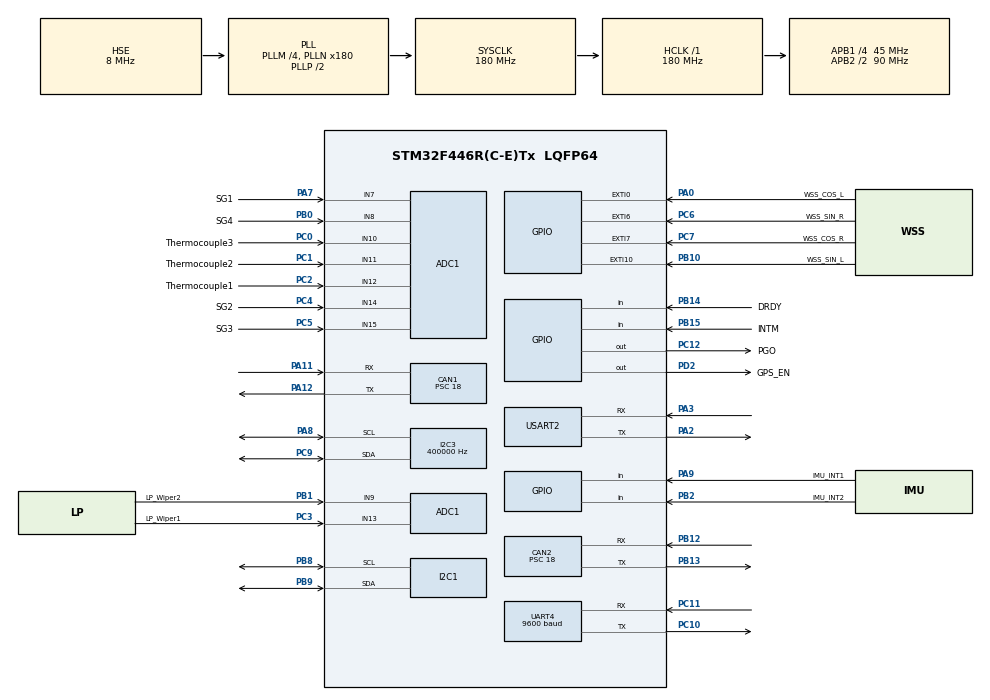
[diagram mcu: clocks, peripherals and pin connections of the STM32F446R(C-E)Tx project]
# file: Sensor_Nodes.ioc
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ADC1.Channel-0\#ChannelRegularConversion=ADC_CHANNEL_13
ADC1.NbrOfConversionFlag=1
ADC1.Rank-0\#ChannelRegularConversion=1
ADC1.SamplingTime-0\#ChannelRegularConversion=ADC_SAMPLETIME_3CYCLES
ADC1.master=1
CAN1.BS1=CAN_BS1_3TQ
CAN1.CalculateBaudRate=500000
CAN1.CalculateTimeBit=2000
CAN1.CalculateTimeQuantum=400.0
CAN1.Prescaler=18
CAN2.BS1=CAN_BS1_3TQ
CAN2.CalculateBaudRate=500000
CAN2.CalculateTimeBit=2000
CAN2.CalculateTimeQuantum=400.0
CAN2.Prescaler=18
Dma.Request0=USART2_RX
Dma.Request1=USART2_TX
Dma.Request2=UART4_RX
Dma.Request3=UART4_TX
Dma.UART4_RX.2.Direction=DMA_PERIPH_TO_MEMORY
Dma.UART4_RX.2.FIFOMode=DMA_FIFOMODE_DISABLE
Dma.UART4_RX.2.Instance=DMA1_Stream2
Dma.UART4_RX.2.MemDataAlignment=DMA_MDATAALIGN_BYTE
Dma.UART4_RX.2.MemInc=DMA_MINC_ENABLE
Dma.UART4_RX.2.Mode=DMA_CIRCULAR
Dma.UART4_RX.2.PeriphDataAlignment=DMA_PDATAALIGN_BYTE
Dma.UART4_RX.2.PeriphInc=DMA_PINC_DISABLE
Dma.UART4_RX.2.Priority=DMA_PRIORITY_LOW
Dma.UART4_TX.3.Direction=DMA_MEMORY_TO_PERIPH
Dma.UART4_TX.3.FIFOMode=DMA_FIFOMODE_DISABLE
Dma.UART4_TX.3.Instance=DMA1_Stream4
Dma.UART4_TX.3.MemDataAlignment=DMA_MDATAALIGN_BYTE
Dma.UART4_TX.3.MemInc=DMA_MINC_ENABLE
Dma.UART4_TX.3.Mode=DMA_NORMAL
Dma.UART4_TX.3.PeriphDataAlignment=DMA_PDATAALIGN_BYTE
Dma.UART4_TX.3.PeriphInc=DMA_PINC_DISABLE
Dma.UART4_TX.3.Priority=DMA_PRIORITY_LOW
Dma.USART2_RX.0.Direction=DMA_PERIPH_TO_MEMORY
Dma.USART2_RX.0.FIFOMode=DMA_FIFOMODE_DISABLE
Dma.USART2_RX.0.Instance=DMA1_Stream5
Dma.USART2_RX.0.MemDataAlignment=DMA_MDATAALIGN_BYTE
Dma.USART2_RX.0.MemInc=DMA_MINC_ENABLE
Dma.USART2_RX.0.Mode=DMA_CIRCULAR
Dma.USART2_RX.0.PeriphDataAlignment=DMA_PDATAALIGN_BYTE
Dma.USART2_RX.0.PeriphInc=DMA_PINC_DISABLE
Dma.USART2_RX.0.Priority=DMA_PRIORITY_LOW
Dma.USART2_TX.1.Direction=DMA_MEMORY_TO_PERIPH
Dma.USART2_TX.1.FIFOMode=DMA_FIFOMODE_DISABLE
Dma.USART2_TX.1.Instance=DMA1_Stream6
Dma.USART2_TX.1.MemDataAlignment=DMA_MDATAALIGN_BYTE
Dma.USART2_TX.1.MemInc=DMA_MINC_ENABLE
Dma.USART2_TX.1.Mode=DMA_NORMAL
Dma.USART2_TX.1.PeriphDataAlignment=DMA_PDATAALIGN_BYTE
Dma.USART2_TX.1.PeriphInc=DMA_PINC_DISABLE
Dma.USART2_TX.1.Priority=DMA_PRIORITY_LOW
FREERTOS.CountingSemaphores01=canTxMailboxSem,3,Dynamic,NULL,3
FREERTOS.Mutexes01=canTxMutex,Dynamic,NULL,Available;canRxMutex,Dynamic,NULL,Available;logMutex,Dynamic,NULL,Available;uartTxMutex,Dynamic,NULL,Available
FREERTOS.Queues01=canTxQueue,16,FEB_CAN_Message_t,0,Dynamic,NULL,NULL;canRxQueue,32,FEB_CAN_Message_t,0,Dynamic,NULL,NULL;uartRxQueue,8,FEB_UART_RxQueueMsg_t,0,Dynamic,NULL,NULL
FREERTOS.Tasks01=defaultTask,24,128,StartDefaultTask,Default,NULL,Dynamic,NULL,NULL;uartRxTask,24,1024,StartUartRxTask,As weak,NULL,Dynamic,NULL,NULL;canRxTask,40,1024,StartCanRxTask,As weak,NULL,Dynamic,NULL,NULL;canTxTask,40,1024,StartCanTxTask,As weak,NULL,Dynamic,NULL,NULL;canPubTask,40,512,StartCanPubTask,As weak,NULL,Dynamic,NULL,NULL;sensorTask,32,1024,StartSensorTask,As weak,NULL,Dynamic,NULL,NULL
FREERTOS.configTOTAL_HEAP_SIZE=32768
FREERTOS.configUSE_COUNTING_SEMAPHORES=1
FREERTOS.configUSE_TIMERS=0
I2C3.ClockSpeed=400000
I2C3.I2C_Mode=I2C_Fast
Mcu.Family=STM32F4
Mcu.Name=STM32F446R(C-E)Tx
Mcu.Package=LQFP64
NVIC.CAN1_RX0_IRQn=true\:5\:0\:false\:false\:true\:true\:true\:true\:true
NVIC.CAN1_RX1_IRQn=true\:5\:0\:false\:false\:true\:true\:true\:true\:true
NVIC.CAN1_SCE_IRQn=true\:5\:0\:false\:false\:true\:true\:true\:true\:true
NVIC.CAN1_TX_IRQn=true\:5\:0\:false\:false\:true\:true\:true\:true\:true
NVIC.CAN2_RX0_IRQn=true\:5\:0\:false\:false\:true\:true\:true\:true\:true
NVIC.CAN2_RX1_IRQn=true\:5\:0\:false\:false\:true\:true\:true\:true\:true
NVIC.CAN2_SCE_IRQn=true\:5\:0\:false\:false\:true\:true\:true\:true\:true
NVIC.CAN2_TX_IRQn=true\:5\:0\:false\:false\:true\:true\:true\:true\:true
NVIC.DMA1_Stream2_IRQn=true\:5\:0\:false\:false\:true\:true\:false\:true\:true
NVIC.DMA1_Stream4_IRQn=true\:5\:0\:false\:false\:true\:true\:false\:true\:true
NVIC.DMA1_Stream5_IRQn=true\:5\:0\:false\:false\:true\:true\:false\:true\:true
NVIC.DMA1_Stream6_IRQn=true\:5\:0\:false\:false\:true\:true\:false\:true\:true
NVIC.EXTI0_IRQn=true\:5\:0\:false\:false\:true\:true\:true\:true\:true
NVIC.EXTI15_10_IRQn=true\:5\:0\:false\:false\:true\:true\:true\:true\:true
NVIC.EXTI9_5_IRQn=true\:5\:0\:false\:false\:true\:true\:true\:true\:true
NVIC.PriorityGroup=NVIC_PRIORITYGROUP_4
NVIC.UART4_IRQn=true\:5\:0\:false\:false\:true\:true\:true\:true\:true
NVIC.USART2_IRQn=true\:5\:0\:false\:false\:true\:true\:true\:true\:true
PA0-WKUP.GPIO_Label=WSS_COS_L
PA0-WKUP.GPIO_ModeDefaultEXTI=GPIO_MODE_IT_RISING_FALLING
PA0-WKUP.Signal=GPXTI0
PA11.Mode=CAN_Activate
PA11.Signal=CAN1_RX
PA12.Mode=CAN_Activate
PA12.Signal=CAN1_TX
PA13.Mode=JTAG_5_pins
PA13.Signal=SYS_JTMS-SWDIO
PA14.Mode=JTAG_5_pins
PA14.Signal=SYS_JTCK-SWCLK
PA15.Mode=JTAG_5_pins
PA15.Signal=SYS_JTDI
PA2.Mode=Asynchronous
PA2.Signal=USART2_TX
PA3.Mode=Asynchronous
PA3.Signal=USART2_RX
PA7.GPIO_Label=SG1
PA7.Signal=ADCx_IN7
PA8.Mode=I2C
PA8.Signal=I2C3_SCL
PA9.GPIO_Label=IMU_INT1
PA9.Signal=GPIO_Input
PB0.GPIO_Label=SG4
PB0.Signal=ADCx_IN8
PB1.GPIO_Label=LP_Wiper2
PB1.Signal=ADCx_IN9
PB10.GPIO_Label=WSS_SIN_L
PB10.GPIO_ModeDefaultEXTI=GPIO_MODE_IT_RISING_FALLING
PB10.Signal=GPXTI10
PB12.Mode=CAN_Activate
PB12.Signal=CAN2_RX
PB13.Mode=CAN_Activate
PB13.Signal=CAN2_TX
PB14.GPIO_Label=DRDY
PB14.Signal=GPIO_Input
PB15.GPIO_Label=INTM
PB15.Signal=GPIO_Input
PB2.GPIO_Label=IMU_INT2
PB2.Signal=GPIO_Input
PB3.Mode=JTAG_5_pins
PB3.Signal=SYS_JTDO-SWO
PB4.Mode=JTAG_5_pins
PB4.Signal=SYS_JTRST
PB8.Mode=I2C
PB8.Signal=I2C1_SCL
PB9.Mode=I2C
PB9.Signal=I2C1_SDA
PC0.GPIO_Label=Thermocouple3
PC0.Signal=ADCx_IN10
PC1.GPIO_Label=Thermocouple2
PC1.Signal=ADCx_IN11
PC10.Mode=Asynchronous
PC10.Signal=UART4_TX
PC11.Mode=Asynchronous
PC11.Signal=UART4_RX
PC12.GPIO_Label=PGO
PC12.Signal=GPIO_Output
PC2.GPIO_Label=Thermocouple1
PC2.Signal=ADCx_IN12
PC3.GPIO_Label=LP_Wiper1
PC3.Signal=SharedAnalog_PC3
PC4.GPIO_Label=SG2
PC4.Signal=ADCx_IN14
PC5.GPIO_Label=SG3
PC5.Signal=ADCx_IN15
PC6.GPIO_Label=WSS_SIN_R
PC6.GPIO_ModeDefaultEXTI=GPIO_MODE_IT_RISING_FALLING
PC6.Signal=GPXTI6
PC7.GPIO_Label=WSS_COS_R
PC7.GPIO_ModeDefaultEXTI=GPIO_MODE_IT_RISING_FALLING
PC7.Signal=GPXTI7
PC9.Mode=I2C
PC9.Signal=I2C3_SDA
PD2.GPIO_Label=GPS_EN
PD2.Signal=GPIO_Output
PH0-OSC_IN.Mode=HSE-External-Oscillator
PH0-OSC_IN.Signal=RCC_OSC_IN
PH1-OSC_OUT.Mode=HSE-External-Oscillator
PH1-OSC_OUT.Signal=RCC_OSC_OUT
ProjectManager.HeapSize=0x200
ProjectManager.StackSize=0x400
ProjectManager.TargetToolchain=CMake
RCC.AHBFreq_Value=180000000
RCC.APB1CLKDivider=RCC_HCLK_DIV4
RCC.APB1Freq_Value=45000000
RCC.APB1TimFreq_Value=90000000
RCC.APB2CLKDivider=RCC_HCLK_DIV2
RCC.APB2Freq_Value=90000000
RCC.APB2TimFreq_Value=180000000
RCC.CortexFreq_Value=180000000
RCC.HCLKFreq_Value=180000000
RCC.HSE_VALUE=8000000
RCC.PLLM=4
RCC.PLLN=180
RCC.PLLSourceVirtual=RCC_PLLSOURCE_HSE
RCC.SYSCLKFreq_VALUE=180000000
RCC.SYSCLKSource=RCC_SYSCLKSOURCE_PLLCLK
RCC.USBFreq_Value=180000000
RCC.VCOOutputFreq_Value=360000000
SH.ADCx_IN10.0=ADC1_IN10,IN10
SH.ADCx_IN11.0=ADC1_IN11,IN11
SH.ADCx_IN12.0=ADC1_IN12,IN12
SH.ADCx_IN14.0=ADC1_IN14,IN14
SH.ADCx_IN15.0=ADC1_IN15,IN15
SH.ADCx_IN7.0=ADC1_IN7,IN7
SH.ADCx_IN8.0=ADC1_IN8,IN8
SH.ADCx_IN9.0=ADC1_IN9,IN9
SH.SharedAnalog_PC3.0=GPIO_Analog
SH.SharedAnalog_PC3.1=ADC1_IN13,IN13
TIM5.AutoReloadPreload=TIM_AUTORELOAD_PRELOAD_DISABLE
TIM5.Period=4294967295
TIM5.Prescaler=89
UART4.BaudRate=9600
UART4.VirtualMode=Asynchronous
USART2.VirtualMode=VM_ASYNC
VP_FREERTOS_VS_CMSIS_V2.Mode=CMSIS_V2
VP_TIM5_VS_ClockSourceINT.Mode=Internal
board=custom

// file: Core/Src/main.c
/* USER CODE BEGIN Header */
/**
  ******************************************************************************
  * @file           : main.c
  * @brief          : Main program body
  ******************************************************************************
  * @attention
  *
  * Copyright (c) 2026 STMicroelectronics.
  * All rights reserved.
  *
  * This software is licensed under terms that can be found in the LICENSE file
  * in the root directory of this software component.
  * If no LICENSE file comes with this software, it is provided AS-IS.
  *
  ******************************************************************************
  */
/* USER CODE END Header */
#include "main.h"
#include "cmsis_os.h"
#include "adc.h"
#include "can.h"
#include "dma.h"
#include "i2c.h"
#include "tim.h"
#include "usart.h"
#include "gpio.h"

void SystemClock_Config(void);
void MX_FREERTOS_Init(void);

int main(void)
{

  /* MCU Configuration--------------------------------------------------------*/

  /* Reset of all peripherals, Initializes the Flash interface and the Systick. */
  HAL_Init();

  /* Configure the system clock */
  SystemClock_Config();

  /* Initialize all configured peripherals */
  MX_GPIO_Init();
  MX_DMA_Init();
  MX_USART2_UART_Init();
  MX_ADC1_Init();
  MX_CAN1_Init();
  MX_CAN2_Init();
  MX_I2C3_Init();
  MX_UART4_Init();
  MX_I2C1_Init();
  MX_TIM5_Init();

  /* Init scheduler */
  osKernelInitialize();  /* Call init function for freertos objects (in cmsis_os2.c) */
  MX_FREERTOS_Init();

  /* Start scheduler */
  osKernelStart();

  /* We should never get here as control is now taken by the scheduler */

  /* Infinite loop */
  while (1)
  {

  }
}

void SystemClock_Config(void)
{
  RCC_OscInitTypeDef RCC_OscInitStruct = {0};
  RCC_ClkInitTypeDef RCC_ClkInitStruct = {0};

  /** Configure the main internal regulator output voltage
  */
  __HAL_RCC_PWR_CLK_ENABLE();
  __HAL_PWR_VOLTAGESCALING_CONFIG(PWR_REGULATOR_VOLTAGE_SCALE1);

  /** Initializes the RCC Oscillators according to the specified parameters
  * in the RCC_OscInitTypeDef structure.
  */
  RCC_OscInitStruct.OscillatorType = RCC_OSCILLATORTYPE_HSE;
  RCC_OscInitStruct.HSEState = RCC_HSE_ON;
  RCC_OscInitStruct.PLL.PLLState = RCC_PLL_ON;
  RCC_OscInitStruct.PLL.PLLSource = RCC_PLLSOURCE_HSE;
  RCC_OscInitStruct.PLL.PLLM = 4;
  RCC_OscInitStruct.PLL.PLLN = 180;
  RCC_OscInitStruct.PLL.PLLP = RCC_PLLP_DIV2;
  RCC_OscInitStruct.PLL.PLLQ = 2;
  RCC_OscInitStruct.PLL.PLLR = 2;
  if (HAL_RCC_OscConfig(&RCC_OscInitStruct) != HAL_OK)
  {
    Error_Handler();
  }

  /** Activate the Over-Drive mode
  */
  if (HAL_PWREx_EnableOverDrive() != HAL_OK)
  {
    Error_Handler();
  }

  /** Initializes the CPU, AHB and APB buses clocks
  */
  RCC_ClkInitStruct.ClockType = RCC_CLOCKTYPE_HCLK|RCC_CLOCKTYPE_SYSCLK
                              |RCC_CLOCKTYPE_PCLK1|RCC_CLOCKTYPE_PCLK2;
  RCC_ClkInitStruct.SYSCLKSource = RCC_SYSCLKSOURCE_PLLCLK;
  RCC_ClkInitStruct.AHBCLKDivider = RCC_SYSCLK_DIV1;
  RCC_ClkInitStruct.APB1CLKDivider = RCC_HCLK_DIV4;
  RCC_ClkInitStruct.APB2CLKDivider = RCC_HCLK_DIV2;

  if (HAL_RCC_ClockConfig(&RCC_ClkInitStruct, FLASH_LATENCY_5) != HAL_OK)
  {
    Error_Handler();
  }
}

void Error_Handler(void)
{
  __disable_irq();
  while (1)
  {
  }
}

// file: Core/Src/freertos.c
/* USER CODE BEGIN Header */
/**
  ******************************************************************************
  * File Name          : freertos.c
  * Description        : Code for freertos applications
  ******************************************************************************
  * @attention
  *
  * Copyright (c) 2026 STMicroelectronics.
  * All rights reserved.
  *
  * This software is licensed under terms that can be found in the LICENSE file
  * in the root directory of this software component.
  * If no LICENSE file comes with this software, it is provided AS-IS.
  *
  ******************************************************************************
  */
/* USER CODE END Header */

#include "FreeRTOS.h"
#include "task.h"
#include "main.h"
#include "cmsis_os.h"

/* USER CODE BEGIN Includes */
#include "FEB_Main.h"
#include "feb_can_lib.h"
#include "feb_uart.h"
/* USER CODE END Includes */

/* Definitions for defaultTask */
osThreadId_t defaultTaskHandle;
const osThreadAttr_t defaultTask_attributes = {
  .name = "defaultTask",
  .stack_size = 128 * 4,
  .priority = (osPriority_t) osPriorityNormal,
};
/* Definitions for uartRxTask */
osThreadId_t uartRxTaskHandle;
const osThreadAttr_t uartRxTask_attributes = {
  .name = "uartRxTask",
  .stack_size = 1024 * 4,
  .priority = (osPriority_t) osPriorityNormal,
};
/* Definitions for canRxTask */
osThreadId_t canRxTaskHandle;
const osThreadAttr_t canRxTask_attributes = {
  .name = "canRxTask",
  .stack_size = 1024 * 4,
  .priority = (osPriority_t) osPriorityHigh,
};
/* Definitions for canTxTask */
osThreadId_t canTxTaskHandle;
const osThreadAttr_t canTxTask_attributes = {
  .name = "canTxTask",
  .stack_size = 1024 * 4,
  .priority = (osPriority_t) osPriorityHigh,
};
/* Definitions for canPubTask */
osThreadId_t canPubTaskHandle;
const osThreadAttr_t canPubTask_attributes = {
  .name = "canPubTask",
  .stack_size = 512 * 4,
  .priority = (osPriority_t) osPriorityHigh,
};
/* Definitions for sensorTask */
osThreadId_t sensorTaskHandle;
const osThreadAttr_t sensorTask_attributes = {
  .name = "sensorTask",
  .stack_size = 1024 * 4,
  .priority = (osPriority_t) osPriorityAboveNormal,
};
/* Definitions for canTxQueue */
osMessageQueueId_t canTxQueueHandle;
const osMessageQueueAttr_t canTxQueue_attributes = {
  .name = "canTxQueue"
};
/* Definitions for canRxQueue */
osMessageQueueId_t canRxQueueHandle;
const osMessageQueueAttr_t canRxQueue_attributes = {
  .name = "canRxQueue"
};
/* Definitions for uartRxQueue */
osMessageQueueId_t uartRxQueueHandle;
const osMessageQueueAttr_t uartRxQueue_attributes = {
  .name = "uartRxQueue"
};
/* Definitions for canTxMutex */
osMutexId_t canTxMutexHandle;
const osMutexAttr_t canTxMutex_attributes = {
  .name = "canTxMutex"
};
/* Definitions for canRxMutex */
osMutexId_t canRxMutexHandle;
const osMutexAttr_t canRxMutex_attributes = {
  .name = "canRxMutex"
};
/* Definitions for logMutex */
osMutexId_t logMutexHandle;
const osMutexAttr_t logMutex_attributes = {
  .name = "logMutex"
};
/* Definitions for uartTxMutex */
osMutexId_t uartTxMutexHandle;
const osMutexAttr_t uartTxMutex_attributes = {
  .name = "uartTxMutex"
};
/* Definitions for canTxMailboxSem */
osSemaphoreId_t canTxMailboxSemHandle;
const osSemaphoreAttr_t canTxMailboxSem_attributes = {
  .name = "canTxMailboxSem"
};

void StartDefaultTask(void *argument);
void StartUartRxTask(void *argument);
void StartCanRxTask(void *argument);
void StartCanTxTask(void *argument);
void StartCanPubTask(void *argument);
void StartSensorTask(void *argument);

void MX_FREERTOS_Init(void); /* (MISRA C 2004 rule 8.1) */

void MX_FREERTOS_Init(void) {
  /* Create the mutex(es) */
  /* creation of canTxMutex */
  canTxMutexHandle = osMutexNew(&canTxMutex_attributes);

  /* creation of canRxMutex */
  canRxMutexHandle = osMutexNew(&canRxMutex_attributes);

  /* creation of logMutex */
  logMutexHandle = osMutexNew(&logMutex_attributes);

  /* creation of uartTxMutex */
  uartTxMutexHandle = osMutexNew(&uartTxMutex_attributes);

  /* Create the semaphores(s) */
  /* creation of canTxMailboxSem */
  canTxMailboxSemHandle = osSemaphoreNew(3, 3, &canTxMailboxSem_attributes);

  /* Create the queue(s) */
  /* creation of canTxQueue */
  canTxQueueHandle = osMessageQueueNew (16, sizeof(FEB_CAN_Message_t), &canTxQueue_attributes);

  /* creation of canRxQueue */
  canRxQueueHandle = osMessageQueueNew (32, sizeof(FEB_CAN_Message_t), &canRxQueue_attributes);

  /* creation of uartRxQueue */
  uartRxQueueHandle = osMessageQueueNew (8, sizeof(FEB_UART_RxQueueMsg_t), &uartRxQueue_attributes);

  /* Create the thread(s) */
  /* creation of defaultTask */
  defaultTaskHandle = osThreadNew(StartDefaultTask, NULL, &defaultTask_attributes);

  /* creation of uartRxTask */
  uartRxTaskHandle = osThreadNew(StartUartRxTask, NULL, &uartRxTask_attributes);

  /* creation of canRxTask */
  canRxTaskHandle = osThreadNew(StartCanRxTask, NULL, &canRxTask_attributes);

  /* creation of canTxTask */
  canTxTaskHandle = osThreadNew(StartCanTxTask, NULL, &canTxTask_attributes);

  /* creation of canPubTask */
  canPubTaskHandle = osThreadNew(StartCanPubTask, NULL, &canPubTask_attributes);

  /* creation of sensorTask */
  sensorTaskHandle = osThreadNew(StartSensorTask, NULL, &sensorTask_attributes);

  /* USER CODE BEGIN RTOS_EVENTS */
  SN_Init();
  /* add events, ... */
  /* USER CODE END RTOS_EVENTS */

}

void StartDefaultTask(void *argument)
{
  for(;;)
  {
    osDelay(1);
  }
}

__weak void StartUartRxTask(void *argument)
{
  for(;;)
  {
    osDelay(1);
  }
}

__weak void StartCanRxTask(void *argument)
{
  for(;;)
  {
    osDelay(1);
  }
}

__weak void StartCanTxTask(void *argument)
{
  for(;;)
  {
    osDelay(1);
  }
}

__weak void StartCanPubTask(void *argument)
{
  for(;;)
  {
    osDelay(1);
  }
}

__weak void StartSensorTask(void *argument)
{
  for(;;)
  {
    osDelay(1);
  }
}
